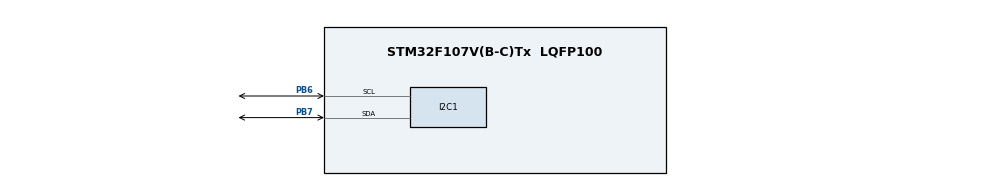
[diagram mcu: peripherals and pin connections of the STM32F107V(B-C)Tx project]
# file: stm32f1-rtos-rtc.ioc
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Mcu.Family=STM32F1
FREERTOS.Tasks01=defaultTask,0,128,StartDefaultTask,Default,NULL,Dynamic,NULL,NULL;rtc_task,-3,128,rtc_entry,Default,NULL,Dynamic,NULL,NULL
PA14.Mode=Serial_Wire
PB7.Signal=I2C1_SDA
VP_FREERTOS_VS_CMSIS_V1.Mode=CMSIS_V1
PA13.Mode=Serial_Wire
Mcu.Name=STM32F107V(B-C)Tx
Mcu.Package=LQFP100
ProjectManager.StackSize=0x400
OSC_IN.Mode=HSE-External-Oscillator
PA13.Signal=SYS_JTMS-SWDIO
PB7.Mode=I2C
PA14.Signal=SYS_JTCK-SWCLK
ProjectManager.HeapSize=0x200
ProjectManager.TargetToolchain=STM32CubeIDE
NVIC.PriorityGroup=NVIC_PRIORITYGROUP_4
PB6.Signal=I2C1_SCL
PB6.Mode=I2C
OSC_IN.Signal=RCC_OSC_IN
RCC.USBFreq_Value=10666666.666666666
OSC_OUT.Mode=HSE-External-Oscillator
OSC_OUT.Signal=RCC_OSC_OUT
board=custom

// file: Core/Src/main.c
/* USER CODE BEGIN Header */
/**
  ******************************************************************************
  * @file           : main.c
  * @brief          : Main program body
  ******************************************************************************
  * @attention
  *
  * <h2><center>&copy; Copyright (c) 2021 STMicroelectronics.
  * All rights reserved.</center></h2>
  *
  * This software component is licensed by ST under BSD 3-Clause license,
  * the "License"; You may not use this file except in compliance with the
  * License. You may obtain a copy of the License at:
  *                        opensource.org/licenses/BSD-3-Clause
  *
  ******************************************************************************
  */
/* USER CODE END Header */
#include "main.h"
#include "cmsis_os.h"

/* USER CODE BEGIN Includes */
#include "stdio.h"
#include "ds1307_for_stm32_hal.h"
/* USER CODE END Includes */

/* USER CODE BEGIN PTD */
typedef struct {
	uint8_t	sec;
	uint8_t min;
	uint8_t hour;
	uint8_t dow;
	uint8_t date;
	uint8_t month;
	uint16_t year;
}DS1307_STRUCT;
DS1307_STRUCT	ds1307;
/* USER CODE END PTD */

I2C_HandleTypeDef hi2c1;

osThreadId defaultTaskHandle;
osThreadId rtc_taskHandle;

void SystemClock_Config(void);
static void MX_GPIO_Init(void);
static void MX_I2C1_Init(void);
void StartDefaultTask(void const * argument);
void rtc_entry(void const * argument);

/* USER CODE BEGIN 0 */
/* Lookup table for the days of week. */
const char *DAYS_OF_WEEK[7] = { "Sunday", "Monday", "Tuesday", "Wednesday", "Thursday", "Friday", "Saturday" };
char buffer[100] = { 0 };

uint8_t date;

/* USER CODE END 0 */

int main(void)
{

  /* MCU Configuration--------------------------------------------------------*/

  /* Reset of all peripherals, Initializes the Flash interface and the Systick. */
  HAL_Init();

  /* Configure the system clock */
  SystemClock_Config();

  /* Initialize all configured peripherals */
  MX_GPIO_Init();
  MX_I2C1_Init();

  /* Create the thread(s) */
  /* definition and creation of defaultTask */
  osThreadDef(defaultTask, StartDefaultTask, osPriorityNormal, 0, 128);
  defaultTaskHandle = osThreadCreate(osThread(defaultTask), NULL);

  /* definition and creation of rtc_task */
  osThreadDef(rtc_task, rtc_entry, osPriorityIdle, 0, 128);
  rtc_taskHandle = osThreadCreate(osThread(rtc_task), NULL);

  /* Start scheduler */
  osKernelStart();

  /* We should never get here as control is now taken by the scheduler */
  /* Infinite loop */
  while (1)
  {

  }
}

void SystemClock_Config(void)
{
  RCC_OscInitTypeDef RCC_OscInitStruct = {0};
  RCC_ClkInitTypeDef RCC_ClkInitStruct = {0};

  /** Initializes the RCC Oscillators according to the specified parameters
  * in the RCC_OscInitTypeDef structure.
  */
  RCC_OscInitStruct.OscillatorType = RCC_OSCILLATORTYPE_HSI;
  RCC_OscInitStruct.HSIState = RCC_HSI_ON;
  RCC_OscInitStruct.HSICalibrationValue = RCC_HSICALIBRATION_DEFAULT;
  RCC_OscInitStruct.PLL.PLLState = RCC_PLL_NONE;
  RCC_OscInitStruct.PLL2.PLL2State = RCC_PLL_NONE;
  if (HAL_RCC_OscConfig(&RCC_OscInitStruct) != HAL_OK)
  {
    Error_Handler();
  }
  /** Initializes the CPU, AHB and APB buses clocks
  */
  RCC_ClkInitStruct.ClockType = RCC_CLOCKTYPE_HCLK|RCC_CLOCKTYPE_SYSCLK
                              |RCC_CLOCKTYPE_PCLK1|RCC_CLOCKTYPE_PCLK2;
  RCC_ClkInitStruct.SYSCLKSource = RCC_SYSCLKSOURCE_HSI;
  RCC_ClkInitStruct.AHBCLKDivider = RCC_SYSCLK_DIV1;
  RCC_ClkInitStruct.APB1CLKDivider = RCC_HCLK_DIV1;
  RCC_ClkInitStruct.APB2CLKDivider = RCC_HCLK_DIV1;

  if (HAL_RCC_ClockConfig(&RCC_ClkInitStruct, FLASH_LATENCY_0) != HAL_OK)
  {
    Error_Handler();
  }
  /** Configure the Systick interrupt time
  */
  __HAL_RCC_PLLI2S_ENABLE();
}

static void MX_I2C1_Init(void)
{

  hi2c1.Instance = I2C1;
  hi2c1.Init.ClockSpeed = 100000;
  hi2c1.Init.DutyCycle = I2C_DUTYCYCLE_2;
  hi2c1.Init.OwnAddress1 = 0;
  hi2c1.Init.AddressingMode = I2C_ADDRESSINGMODE_7BIT;
  hi2c1.Init.DualAddressMode = I2C_DUALADDRESS_DISABLE;
  hi2c1.Init.OwnAddress2 = 0;
  hi2c1.Init.GeneralCallMode = I2C_GENERALCALL_DISABLE;
  hi2c1.Init.NoStretchMode = I2C_NOSTRETCH_DISABLE;
  if (HAL_I2C_Init(&hi2c1) != HAL_OK)
  {
    Error_Handler();
  }

}

static void MX_GPIO_Init(void)
{

  /* GPIO Ports Clock Enable */
  __HAL_RCC_GPIOA_CLK_ENABLE();
  __HAL_RCC_GPIOB_CLK_ENABLE();

}

void StartDefaultTask(void const * argument)
{
  for(;;)
  {
    osDelay(1);
  }
}

void rtc_entry(void const * argument)
{
  /* USER CODE BEGIN rtc_entry */
	/* Start DS1307 timing. Pass user I2C handle pointer to function. */
	DS1307_Init(&hi2c1);
	/* To test leap year correction. */
	DS1307_SetTimeZone(+8, 00);
	DS1307_SetDate(29);
	DS1307_SetMonth(2);
	DS1307_SetYear(2024);
	DS1307_SetDayOfWeek(4);
	DS1307_SetHour(23);
	DS1307_SetMinute(59);
	DS1307_SetSecond(30);
  /* Infinite loop */
  for(;;)
  {
	/* Get current date and time. */
	  ds1307.date = DS1307_GetDate();
	  ds1307.month  = DS1307_GetMonth();
	  ds1307.year = DS1307_GetYear();
	  ds1307.dow = DS1307_GetDayOfWeek();
	  ds1307.hour = DS1307_GetHour();
	  ds1307.min = DS1307_GetMinute();
	  ds1307.sec = DS1307_GetSecond();
	int8_t zone_hr = DS1307_GetTimeZoneHour();
	uint8_t zone_min = DS1307_GetTimeZoneMin();
    osDelay(1);
  }
  /* USER CODE END rtc_entry */
}

void Error_Handler(void)
{
  __disable_irq();
  while (1)
  {
  }
}

/************************ (C) COPYRIGHT STMicroelectronics *****END OF FILE****/
